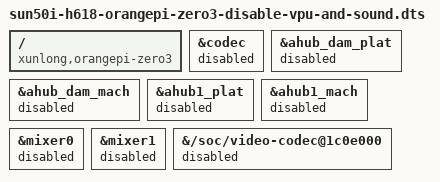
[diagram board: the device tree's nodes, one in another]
/dts-v1/;
/plugin/;

/ {
	compatible = "xunlong,orangepi-zero3";
	fragment@0 {
		target = <&codec>;
		__overlay__ {
			status = "disabled";
		};
	};

	fragment@1 {
		target = <&ahub_dam_plat>;
		__overlay__ {
			status = "disabled";
		};
	};

	fragment@2 {
		target = <&ahub_dam_mach>;
		__overlay__ {
			status = "disabled";
		};
	};

	fragment@3 {
		target = <&ahub1_plat>;
		__overlay__ {
			status = "disabled";
		};
	};

	fragment@4 {
		target = <&ahub1_mach>;
		__overlay__ {
			status = "disabled";
		};
	};

	fragment@5 {
		target = <&mixer0>;
		__overlay__ {
			status = "disabled";
		};
	};

	fragment@6 {
		target = <&mixer1>;
		__overlay__ {
			status = "disabled";
		};
	};

	fragment@7 {
		target-path = "/soc/video-codec@1c0e000";
		__overlay__ {
			status = "disabled";
		};
	};
};
